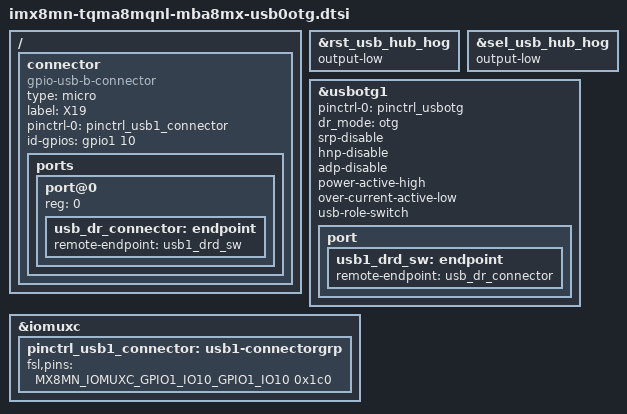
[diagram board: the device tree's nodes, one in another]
// SPDX-License-Identifier: (GPL-2.0-or-later OR MIT)
/*
 * Copyright 2020-2022 TQ-Systems GmbH
 * Author: Alexander Stein <linux@ew.tq-group.com>
 */

/ {
	connector {
		compatible = "gpio-usb-b-connector", "usb-b-connector";
		type = "micro";
		label = "X19";
		pinctrl-names = "default";
		pinctrl-0 = <&pinctrl_usb1_connector>;
		id-gpios = <&gpio1 10 GPIO_ACTIVE_HIGH>;

		ports {
			#address-cells = <1>;
			#size-cells = <0>;

			port@0 {
				reg = <0>;
				usb_dr_connector: endpoint {
					remote-endpoint = <&usb1_drd_sw>;
				};
			};
		};
	};
};

&rst_usb_hub_hog {
	output-low;
};

&sel_usb_hub_hog {
	output-low;
};

&usbotg1 {
	pinctrl-names = "default";
	pinctrl-0 = <&pinctrl_usbotg>;
	dr_mode = "otg";
	srp-disable;
	hnp-disable;
	adp-disable;
	power-active-high;
	over-current-active-low;
	usb-role-switch;
	status = "okay";

	port {
		usb1_drd_sw: endpoint {
			remote-endpoint = <&usb_dr_connector>;
		};
	};
};

&iomuxc {
	pinctrl_usb1_connector: usb1-connectorgrp {
		fsl,pins = <MX8MN_IOMUXC_GPIO1_IO10_GPIO1_IO10		0x1c0>;
	};
};
